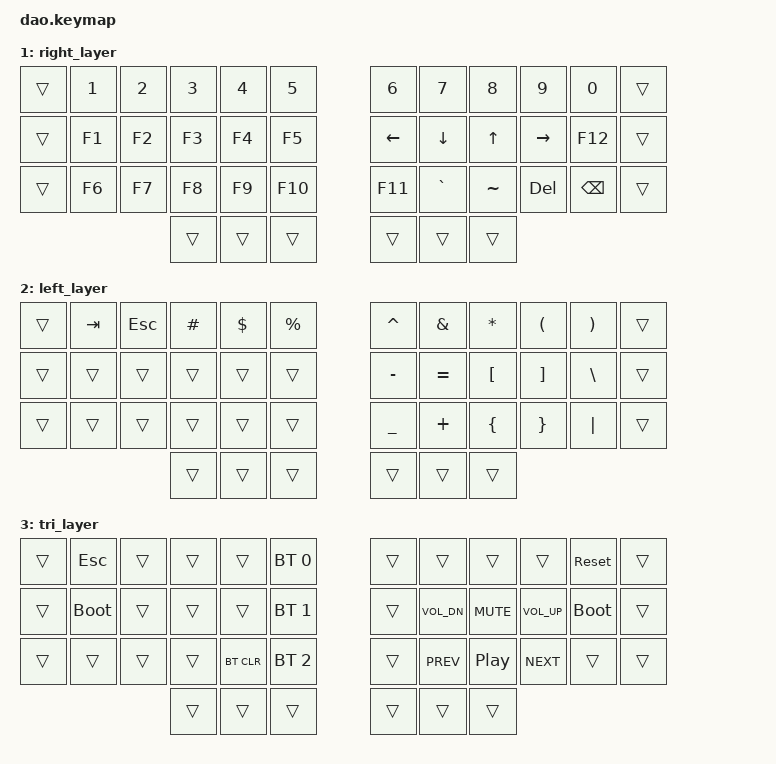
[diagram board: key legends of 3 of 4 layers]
// Copyright (c) 2022 The ZMK Contributors
// SPDX-License-Identifier: MIT

#include <behaviors.dtsi>
#include <dt-bindings/zmk/keys.h>
#include <dt-bindings/zmk/bt.h>

// Home row mods macro
#define HRML(k1,k2,k3,k4) &ht LSHFT k1  &ht LCTRL k2  &ht LALT k3  &ht LGUI k4
#define HRMR(k1,k2,k3,k4) &ht RGUI k1  &ht RALT k2  &ht RCTRL k3  &ht RSHFT k4

/ {
    behaviors {
        ht: hold_tap {
            compatible = "zmk,behavior-hold-tap";
            #binding-cells = <2>;
            flavor = "tap-preferred";
            tapping-term-ms = <220>;
            quick-tap-ms = <150>;
            require-prior-idle-ms = <100>;
            bindings = <&kp>, <&kp>;
        };
    };

    conditional_layers {
        compatible = "zmk,conditional-layers";
        tri_layer {
            if-layers = <1 2>;
            then-layer = <3>;
        };
    };

    keymap {
        compatible = "zmk,keymap";
        default_layer {
            bindings = <
        //╭──────────┬──────────┬──────────┬──────────┬──────────┬──────────╮   ╭──────────┬──────────┬──────────┬──────────┬──────────┬──────────╮
        //│          │  Q       │  W       │  E       │  R       │  T       │   │  Y       │  U       │  I       │  O       │  P       │          │
            &none      &kp Q      &kp W      &kp E      &kp R      &kp T          &kp Y      &kp U      &kp I      &kp O      &kp P      &none
        //├──────────┼──────────┼──────────┼──────────┼──────────┼──────────┤   ├──────────┼──────────┼──────────┼──────────┼──────────┼──────────┤
        //│          │  A       │  S       │  D       │  F       │  G       │   │  H       │  J       │  K       │  L       │ ' "      │          │
            &none      HRML(A,        S,         D,         F)     &kp G          &kp H      HRMR(J,        K,         L,        SEMI)    &none
        //├──────────┼──────────┼──────────┼──────────┼──────────┼──────────┤   ├──────────┼──────────┼──────────┼──────────┼──────────┼──────────┤
        //│          │  Z       │  X       │  C       │  V       │  B       │   │  N       │  M       │ , <      │ . >      │ / ?      │          │
            &none      &kp Z      &kp X      &kp C      &kp V      &kp B          &kp N      &kp M      &kp COMMA  &kp DOT    &kp FSLH   &none
        //╰──────────┴──────────┴──────────┼──────────┼──────────┼──────────┤   ├──────────┼──────────┼──────────┼──────────┴──────────┴──────────╯
                                             &none      &mo 1      &kp SPC        &kp RET    &mo 2      &none
        //                                 ╰──────────┴──────────┴──────────╯   ╰──────────┴──────────┴──────────╯
            >;
        };

        right_layer {
            bindings = <
        //╭──────────┬──────────┬──────────┬──────────┬──────────┬──────────╮   ╭──────────┬──────────┬──────────┬──────────┬──────────┬──────────╮
        //│          │  1       │  2       │  3       │  4       │  5       │   │  6       │  7       │  8       │  9       │  0       │          │
            &trans     &kp N1     &kp N2     &kp N3     &kp N4     &kp N5         &kp N6     &kp N7     &kp N8     &kp N9     &kp N0     &trans
        //├──────────┼──────────┼──────────┼──────────┼──────────┼──────────┤   ├──────────┼──────────┼──────────┼──────────┼──────────┼──────────┤
        //│          │  F1      │  F2      │  F3      │  F4      │  F5      │   │ LEFT     │ DOWN     │ UP       │ RIGHT    │  F12     │          │
            &trans     &kp F1     &kp F2     &kp F3     &kp F4     &kp F5         &kp LEFT   &kp DOWN   &kp UP     &kp RIGHT  &kp F12    &trans
        //├──────────┼──────────┼──────────┼──────────┼──────────┼──────────┤   ├──────────┼──────────┼──────────┼──────────┼──────────┼──────────┤
        //│          │  F6      │  F7      │  F8      │  F9      │  F10     │   │  F11     │  `       │  ~       │  DEL     │  BSPC    │          │
            &trans     &kp F6     &kp F7     &kp F8     &kp F9     &kp F10        &kp F11    &kp GRAVE  &kp TILDE  &kp DEL    &kp BSPC   &trans
        //╰──────────┴──────────┴──────────┼──────────┼──────────┼──────────┤   ├──────────┼──────────┼──────────┼──────────┴──────────┴──────────╯
                                             &trans     &trans     &trans         &trans     &trans     &trans
        //                                 ╰──────────┴──────────┴──────────╯   ╰──────────┴──────────┴──────────╯
            >;
        };

        left_layer {
            bindings = <
        //╭──────────┬──────────┬──────────┬──────────┬──────────┬──────────╮   ╭──────────┬──────────┬──────────┬──────────┬──────────┬──────────╮
        //│          │  TAB     │  ESC     │  #       │  $       │  %       │   │  ^       │  &       │  *       │  (       │  )       │          │
            &trans     &kp TAB    &kp ESC    &kp HASH   &kp DLLR   &kp PRCNT      &kp CARET  &kp AMPS   &kp ASTRK  &kp LPAR   &kp RPAR   &trans
        //├──────────┼──────────┼──────────┼──────────┼──────────┼──────────┤   ├──────────┼──────────┼──────────┼──────────┼──────────┼──────────┤
        //│          │          │          │          │          │          │   │  -       │  =       │  [       │  ]       │  \       │          │
            &trans     &trans     &trans     &trans     &trans     &trans         &kp MINUS  &kp EQUAL  &kp LBKT   &kp RBKT   &kp BSLH   &trans
        //├──────────┼──────────┼──────────┼──────────┼──────────┼──────────┤   ├──────────┼──────────┼──────────┼──────────┼──────────┼──────────┤
        //│          │          │          │          │          │          │   │  _       │  +       │  {       │  }       │  |       │          │
            &trans     &trans     &trans     &trans     &trans     &trans         &kp UNDER  &kp PLUS   &kp LBRC   &kp RBRC   &kp PIPE   &trans
        //╰──────────┴──────────┴──────────┼──────────┼──────────┼──────────┤   ├──────────┼──────────┼──────────┼──────────┴──────────┴──────────╯
                                             &trans     &trans     &trans         &trans     &trans     &trans
        //                                 ╰──────────┴──────────┴──────────╯   ╰──────────┴──────────┴──────────╯
            >;
        };

        tri_layer {
            bindings = <
        //╭──────────┬──────────┬──────────┬──────────┬──────────┬──────────╮   ╭──────────┬──────────┬──────────┬──────────┬──────────┬──────────╮
        //│          │  ESC     │          │          │          │PROFILE 0 │   │          │          │          │          │  RESET   │          │
            &trans     &kp ESC    &trans     &trans     &trans    &bt BT_SEL 0    &trans     &trans     &trans     &trans    &sys_reset  &trans
        //├──────────┼──────────┼──────────┼──────────┼──────────┼──────────┤   ├──────────┼──────────┼──────────┼──────────┼──────────┼──────────┤
        //│          │BOOTLOADER│          │          │          │PROFILE 1 │   │          │ VOL DOWN │  MUTE    │ VOL UP   │BOOTLOADER│          │
            &trans   &bootloader  &trans     &trans     &trans    &bt BT_SEL 1    &trans     &kp C_VOL_DN &kp C_MUTE &kp C_VOL_UP &bootloader &trans
        //├──────────┼──────────┼──────────┼──────────┼──────────┼──────────┤   ├──────────┼──────────┼──────────┼──────────┼──────────┼──────────┤
        //│          │          │          │          │ CLEAR BT │PROFILE 2 │   │          │ PREV     │ PLAY     │ NEXT     │          │          │
            &trans     &trans     &trans     &trans    &bt BT_CLR &bt BT_SEL 2    &trans     &kp C_PREV &kp C_PP   &kp C_NEXT &trans     &trans
        //╰──────────┴──────────┴──────────┼──────────┼──────────┼──────────┤   ├──────────┼──────────┼──────────┼──────────┴──────────┴──────────╯
                                             &trans     &trans     &trans         &trans     &trans     &trans
        //                                 ╰──────────┴──────────┴──────────╯   ╰──────────┴──────────┴──────────╯
            >;
        };
    };
};
